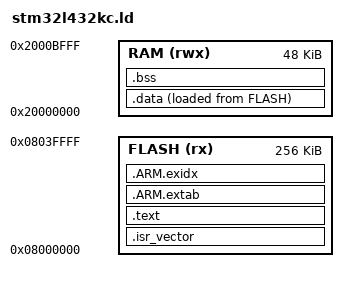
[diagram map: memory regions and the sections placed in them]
ENTRY(Reset_Handler)
MEMORY {
 FLASH (rx) : ORIGIN = 0x08000000, LENGTH = 256K
 RAM (rwx) : ORIGIN = 0x20000000, LENGTH = 48K
}
_estack = ORIGIN(RAM) + LENGTH(RAM);
SECTIONS {
 .isr_vector : { KEEP(*(.isr_vector)) } > FLASH
 .text : { *(.text*) *(.rodata*) . = ALIGN(4); } > FLASH
 .ARM.extab : { *(.ARM.extab*) } > FLASH
 .ARM.exidx : { __exidx_start = .; *(.ARM.exidx*) __exidx_end = .; } > FLASH
 _sidata = LOADADDR(.data);
 .data : { . = ALIGN(4); _sdata = .; *(.data*) . = ALIGN(4); _edata = .; } > RAM AT> FLASH
 .bss (NOLOAD) : { . = ALIGN(4); _sbss = .; *(.bss*) *(COMMON) . = ALIGN(4); _ebss = .; } > RAM
 end = _ebss;
 _end = _ebss;
 __end__ = _ebss;
 ASSERT(_ebss < _estack-4096, "Leave at least 4 KiB stack")
}
